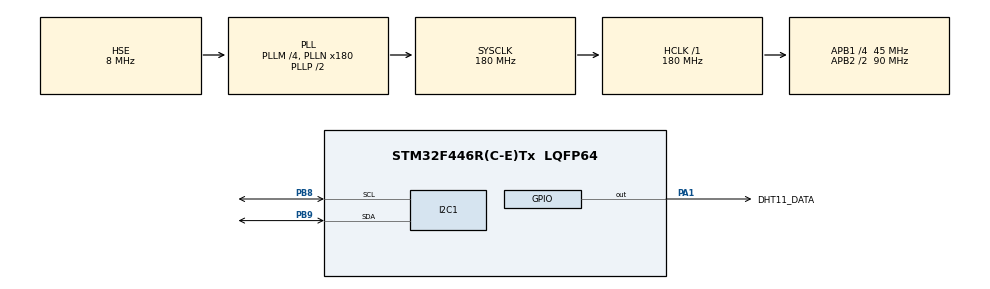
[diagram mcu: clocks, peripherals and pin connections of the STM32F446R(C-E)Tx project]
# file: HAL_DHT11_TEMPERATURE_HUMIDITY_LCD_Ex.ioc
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Mcu.Family=STM32F4
Mcu.Name=STM32F446R(C-E)Tx
Mcu.Package=LQFP64
NVIC.PriorityGroup=NVIC_PRIORITYGROUP_4
NVIC.TIM6_DAC_IRQn=true\:0\:0\:false\:false\:true\:true\:true
PA1.GPIO_Label=DHT11_DATA
PA1.GPIO_PuPd=GPIO_PULLUP
PA1.Signal=GPIO_Output
PB8.Mode=I2C
PB8.Signal=I2C1_SCL
PB9.Mode=I2C
PB9.Signal=I2C1_SDA
PH0-OSC_IN.Mode=HSE-External-Oscillator
PH0-OSC_IN.Signal=RCC_OSC_IN
PH1-OSC_OUT.Mode=HSE-External-Oscillator
PH1-OSC_OUT.Signal=RCC_OSC_OUT
ProjectManager.HeapSize=0x200
ProjectManager.StackSize=0x400
ProjectManager.TargetToolchain=MDK-ARM V5
RCC.AHBFreq_Value=180000000
RCC.APB1CLKDivider=RCC_HCLK_DIV4
RCC.APB1Freq_Value=45000000
RCC.APB1TimFreq_Value=90000000
RCC.APB2CLKDivider=RCC_HCLK_DIV2
RCC.APB2Freq_Value=90000000
RCC.APB2TimFreq_Value=180000000
RCC.CortexFreq_Value=180000000
RCC.HCLKFreq_Value=180000000
RCC.HSE_VALUE=8000000
RCC.PLLM=4
RCC.PLLN=180
RCC.PLLSourceVirtual=RCC_PLLSOURCE_HSE
RCC.SYSCLKFreq_VALUE=180000000
RCC.SYSCLKSource=RCC_SYSCLKSOURCE_PLLCLK
RCC.USBFreq_Value=180000000
RCC.VCOOutputFreq_Value=360000000
TIM6.Period=0x1
TIM6.Prescaler=89
VP_TIM6_VS_ClockSourceINT.Mode=Enable_Timer
board=custom

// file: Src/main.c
/* USER CODE BEGIN Header */
/**
  ******************************************************************************
  * @file           : main.c
  * @brief          : Main program body
  ******************************************************************************
  * @attention
  *
  * <h2><center>&copy; Copyright (c) 2020 STMicroelectronics.
  * All rights reserved.</center></h2>
  *
  * This software component is licensed by ST under BSD 3-Clause license,
  * the "License"; You may not use this file except in compliance with the
  * License. You may obtain a copy of the License at:
  *                        opensource.org/licenses/BSD-3-Clause
  *
  ******************************************************************************
  */
/* USER CODE END Header */

#include "main.h"

/* USER CODE BEGIN Includes */
#include	<stdio.h>
#include	"i2c-lcd.h"
/* USER CODE END Includes */

I2C_HandleTypeDef hi2c1;

TIM_HandleTypeDef htim6;

/* USER CODE BEGIN PV */
uint8_t Rh[2],temp[2],presence=0,var=0;
uint16_t SUM,RH,TEMP;
float temperature=0;
float humidity =0;
/* USER CODE END PV */

void SystemClock_Config(void);
static void MX_GPIO_Init(void);
static void MX_I2C1_Init(void);
static void MX_TIM6_Init(void);
void  Delay_us(uint16_t us);
void set_pin_input(GPIO_TypeDef * GPIO_PORT,uint16_t GPIO_PIN);
void set_pin_output(GPIO_TypeDef * GPIO_PORT,uint16_t GPIO_PIN);
void DHT11_Start(void);
uint8_t DHT11_Check(void);
uint8_t Read_DHT11_data(void);
void	Display_Rh(float Rh);
void	Display_temp(float temp);

/* USER CODE BEGIN 0 */
static void DelayMicroSeconds(uint32_t uSec)
{
	uint32_t uSecVar = uSec;
	uSecVar = uSecVar* ((SystemCoreClock/1000000)/3);
	while(uSecVar--);
}

void DHT11_Start(void)
{
	set_pin_output(DHT11_DATA_GPIO_Port,DHT11_DATA_Pin);		//	data pin selected output pin
	HAL_GPIO_WritePin(DHT11_DATA_GPIO_Port,DHT11_DATA_Pin,GPIO_PIN_RESET);		//	data pin status set high to low
	HAL_Delay(18);		//	18 ms delay from datasheet
	HAL_GPIO_WritePin(DHT11_DATA_GPIO_Port,DHT11_DATA_Pin,GPIO_PIN_SET);		//	data pin status set low to high
	DelayMicroSeconds(20);		//	20 us delay from datasheet
	set_pin_input(DHT11_DATA_GPIO_Port,DHT11_DATA_Pin);		//	data pin selected input pin
}

uint8_t DHT11_Check(void)
{
	uint8_t response=0;
	DelayMicroSeconds(40);		//	delay 40 us
	if (!	HAL_GPIO_ReadPin(DHT11_DATA_GPIO_Port,DHT11_DATA_Pin))	//	read pin state
	{
		DelayMicroSeconds(80);		//	delay 80 us
		if (HAL_GPIO_ReadPin(DHT11_DATA_GPIO_Port,DHT11_DATA_Pin))	//	read pin state
			response=1;
		else
			response=0;
	}
	while(HAL_GPIO_ReadPin(DHT11_DATA_GPIO_Port,DHT11_DATA_Pin));	//	wait for the pin to go low
	return response;
}

uint8_t Read_DHT11_data(void)
{
	uint8_t data=0,j=0;
	for(j=0;j<8;j++)
	{
		while(!	HAL_GPIO_ReadPin(DHT11_DATA_GPIO_Port,DHT11_DATA_Pin));		//	wait for the pin to go high
		DelayMicroSeconds(40);		//	delay 40 us
		if(!HAL_GPIO_ReadPin(DHT11_DATA_GPIO_Port,DHT11_DATA_Pin))
			data &=	~(1<<(7-j));	// after that delay if data pin is low , data is	'0'
		else
			data	|=	(1<<(7-j));	// after that delay if data pin is high , data is	'1'
		while(	HAL_GPIO_ReadPin(DHT11_DATA_GPIO_Port,DHT11_DATA_Pin));		//	wait for the pin to go low
		return	data;
	}
}

void	Display_temp(float temp)
{
	char str[16];
	lcd_put_cur(0,0);

	sprintf(str,"TEMP:%.2f C",temp);
	lcd_send_string(str);

}
void	Display_Rh(float Rh)
{
	char str[16];
	lcd_put_cur(1,0);

	sprintf(str,"HUMIDITY:%.2f ",Rh);
	lcd_send_string(str);
	lcd_send_data('%');
}

void  Delay_us(uint16_t us)
{
	__HAL_TIM_SET_COUNTER(&htim6,0);
	while(__HAL_TIM_GET_COUNTER(&htim6)<us);
}

void set_pin_output(GPIO_TypeDef * GPIO_PORT,uint16_t GPIO_PIN)
{
	GPIO_InitTypeDef GPIO_InitStruct ={0};
	GPIO_InitStruct.Pin = GPIO_PIN;
  GPIO_InitStruct.Mode = GPIO_MODE_OUTPUT_PP;
  GPIO_InitStruct.Pull = GPIO_PULLUP;
  HAL_GPIO_Init(DHT11_DATA_GPIO_Port, &GPIO_InitStruct);
}
void set_pin_input(GPIO_TypeDef * GPIO_PORT,uint16_t GPIO_PIN)
{
	GPIO_InitTypeDef GPIO_InitStruct ={0};
	GPIO_InitStruct.Pin = GPIO_PIN;
  GPIO_InitStruct.Mode = GPIO_MODE_INPUT;
  GPIO_InitStruct.Pull = GPIO_NOPULL;
  HAL_GPIO_Init(DHT11_DATA_GPIO_Port, &GPIO_InitStruct);
}

/* USER CODE END 0 */

int main(void)
{

  /* MCU Configuration--------------------------------------------------------*/

  /* Reset of all peripherals, Initializes the Flash interface and the Systick. */
  HAL_Init();

  /* Configure the system clock */
  SystemClock_Config();

  /* Initialize all configured peripherals */
  MX_GPIO_Init();
  MX_I2C1_Init();
  MX_TIM6_Init();
  /* USER CODE BEGIN 2 */
	lcd_init();

	HAL_TIM_Base_Start(&htim6);
  /* USER CODE END 2 */

  /* Infinite loop */
  /* USER CODE BEGIN WHILE */
  while (1)
  {
		DHT11_Start();
		presence=DHT11_Check();
		Rh[0]=Read_DHT11_data();
		Rh[1]=Read_DHT11_data();
		temp[0]=Read_DHT11_data()	;
		temp[1]=Read_DHT11_data()	;
		SUM=Read_DHT11_data();
		TEMP=temp[0];
		RH=Rh[0];
		temperature=(float)TEMP;
		humidity=(float)RH;

		Display_temp(temperature);
		Display_Rh(humidity);

		HAL_Delay(100);
    /* USER CODE END WHILE */

  }
}

void SystemClock_Config(void)
{
  RCC_OscInitTypeDef RCC_OscInitStruct = {0};
  RCC_ClkInitTypeDef RCC_ClkInitStruct = {0};

  /** Configure the main internal regulator output voltage
  */
  __HAL_RCC_PWR_CLK_ENABLE();
  __HAL_PWR_VOLTAGESCALING_CONFIG(PWR_REGULATOR_VOLTAGE_SCALE1);
  /** Initializes the CPU, AHB and APB busses clocks
  */
  RCC_OscInitStruct.OscillatorType = RCC_OSCILLATORTYPE_HSE;
  RCC_OscInitStruct.HSEState = RCC_HSE_ON;
  RCC_OscInitStruct.PLL.PLLState = RCC_PLL_ON;
  RCC_OscInitStruct.PLL.PLLSource = RCC_PLLSOURCE_HSE;
  RCC_OscInitStruct.PLL.PLLM = 4;
  RCC_OscInitStruct.PLL.PLLN = 180;
  RCC_OscInitStruct.PLL.PLLP = RCC_PLLP_DIV2;
  RCC_OscInitStruct.PLL.PLLQ = 2;
  RCC_OscInitStruct.PLL.PLLR = 2;
  if (HAL_RCC_OscConfig(&RCC_OscInitStruct) != HAL_OK)
  {
    Error_Handler();
  }
  /** Activate the Over-Drive mode
  */
  if (HAL_PWREx_EnableOverDrive() != HAL_OK)
  {
    Error_Handler();
  }
  /** Initializes the CPU, AHB and APB busses clocks
  */
  RCC_ClkInitStruct.ClockType = RCC_CLOCKTYPE_HCLK|RCC_CLOCKTYPE_SYSCLK
                              |RCC_CLOCKTYPE_PCLK1|RCC_CLOCKTYPE_PCLK2;
  RCC_ClkInitStruct.SYSCLKSource = RCC_SYSCLKSOURCE_PLLCLK;
  RCC_ClkInitStruct.AHBCLKDivider = RCC_SYSCLK_DIV1;
  RCC_ClkInitStruct.APB1CLKDivider = RCC_HCLK_DIV4;
  RCC_ClkInitStruct.APB2CLKDivider = RCC_HCLK_DIV2;

  if (HAL_RCC_ClockConfig(&RCC_ClkInitStruct, FLASH_LATENCY_5) != HAL_OK)
  {
    Error_Handler();
  }
}

static void MX_I2C1_Init(void)
{

  hi2c1.Instance = I2C1;
  hi2c1.Init.ClockSpeed = 100000;
  hi2c1.Init.DutyCycle = I2C_DUTYCYCLE_2;
  hi2c1.Init.OwnAddress1 = 0;
  hi2c1.Init.AddressingMode = I2C_ADDRESSINGMODE_7BIT;
  hi2c1.Init.DualAddressMode = I2C_DUALADDRESS_DISABLE;
  hi2c1.Init.OwnAddress2 = 0;
  hi2c1.Init.GeneralCallMode = I2C_GENERALCALL_DISABLE;
  hi2c1.Init.NoStretchMode = I2C_NOSTRETCH_DISABLE;
  if (HAL_I2C_Init(&hi2c1) != HAL_OK)
  {
    Error_Handler();
  }

}

static void MX_TIM6_Init(void)
{

  TIM_MasterConfigTypeDef sMasterConfig = {0};

  htim6.Instance = TIM6;
  htim6.Init.Prescaler = 89;
  htim6.Init.CounterMode = TIM_COUNTERMODE_UP;
  htim6.Init.Period = 0xFFFF-1;
  htim6.Init.AutoReloadPreload = TIM_AUTORELOAD_PRELOAD_DISABLE;
  if (HAL_TIM_Base_Init(&htim6) != HAL_OK)
  {
    Error_Handler();
  }
  sMasterConfig.MasterOutputTrigger = TIM_TRGO_RESET;
  sMasterConfig.MasterSlaveMode = TIM_MASTERSLAVEMODE_DISABLE;
  if (HAL_TIMEx_MasterConfigSynchronization(&htim6, &sMasterConfig) != HAL_OK)
  {
    Error_Handler();
  }

}

static void MX_GPIO_Init(void)
{
  GPIO_InitTypeDef GPIO_InitStruct = {0};

  /* GPIO Ports Clock Enable */
  __HAL_RCC_GPIOH_CLK_ENABLE();
  __HAL_RCC_GPIOA_CLK_ENABLE();
  __HAL_RCC_GPIOB_CLK_ENABLE();

  /*Configure GPIO pin Output Level */
  HAL_GPIO_WritePin(DHT11_DATA_GPIO_Port, DHT11_DATA_Pin, GPIO_PIN_RESET);

  /*Configure GPIO pin : DHT11_DATA_Pin */
  GPIO_InitStruct.Pin = DHT11_DATA_Pin;
  GPIO_InitStruct.Mode = GPIO_MODE_OUTPUT_PP;
  GPIO_InitStruct.Pull = GPIO_NOPULL;
  GPIO_InitStruct.Speed = GPIO_SPEED_FREQ_LOW;
  HAL_GPIO_Init(DHT11_DATA_GPIO_Port, &GPIO_InitStruct);

}

void Error_Handler(void)
{
}

/************************ (C) COPYRIGHT STMicroelectronics *****END OF FILE****/
